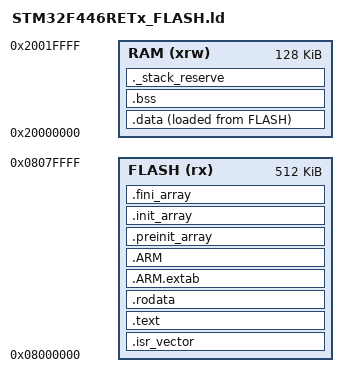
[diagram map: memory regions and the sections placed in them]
/* Linker script for STM32F446RE: 512 KiB Flash @ 0x08000000, 128 KiB SRAM @ 0x20000000. */

ENTRY(Reset_Handler)

/* The stack grows down from the top of SRAM. This much space is reserved below
   .bss and the link fails if the static data would eat into it. There is no heap
   on purpose: the firmware never allocates dynamically. */
_Min_Stack_Size = 0x1000;

MEMORY
{
  FLASH (rx)  : ORIGIN = 0x08000000, LENGTH = 512K
  RAM   (xrw) : ORIGIN = 0x20000000, LENGTH = 128K
}

_estack = ORIGIN(RAM) + LENGTH(RAM);

SECTIONS
{
  .isr_vector :
  {
    . = ALIGN(4);
    KEEP(*(.isr_vector))
    . = ALIGN(4);
  } >FLASH

  .text :
  {
    . = ALIGN(4);
    *(.text)
    *(.text*)
    *(.glue_7)
    *(.glue_7t)
    KEEP(*(.init))
    KEEP(*(.fini))
    . = ALIGN(4);
  } >FLASH

  .rodata :
  {
    . = ALIGN(4);
    *(.rodata)
    *(.rodata*)
    . = ALIGN(4);
  } >FLASH

  .ARM.extab : { *(.ARM.extab* .gnu.linkonce.armextab.*) } >FLASH
  .ARM :
  {
    __exidx_start = .;
    *(.ARM.exidx*)
    __exidx_end = .;
  } >FLASH

  .preinit_array :
  {
    . = ALIGN(4);
    PROVIDE_HIDDEN(__preinit_array_start = .);
    KEEP(*(.preinit_array*))
    PROVIDE_HIDDEN(__preinit_array_end = .);
  } >FLASH

  .init_array :
  {
    . = ALIGN(4);
    PROVIDE_HIDDEN(__init_array_start = .);
    KEEP(*(SORT(.init_array.*)))
    KEEP(*(.init_array*))
    PROVIDE_HIDDEN(__init_array_end = .);
  } >FLASH

  .fini_array :
  {
    . = ALIGN(4);
    PROVIDE_HIDDEN(__fini_array_start = .);
    KEEP(*(SORT(.fini_array.*)))
    KEEP(*(.fini_array*))
    PROVIDE_HIDDEN(__fini_array_end = .);
  } >FLASH

  /* Load address of .data in Flash; the startup code copies it to RAM. */
  _sidata = LOADADDR(.data);

  .data :
  {
    . = ALIGN(4);
    _sdata = .;
    *(.data)
    *(.data*)
    . = ALIGN(4);
    _edata = .;
  } >RAM AT> FLASH

  .bss (NOLOAD) :
  {
    . = ALIGN(4);
    _sbss = .;
    *(.bss)
    *(.bss*)
    *(COMMON)
    . = ALIGN(4);
    _ebss = .;
  } >RAM

  /* Only a size check: fails the link if less than _Min_Stack_Size is left. */
  ._stack_reserve (NOLOAD) :
  {
    . = ALIGN(8);
    PROVIDE(end = .);
    PROVIDE(_end = .);
    . = . + _Min_Stack_Size;
    . = ALIGN(8);
  } >RAM

  .ARM.attributes 0 : { *(.ARM.attributes) }
}
